VERSION ""

NS_ :

BS_:

BU_: VCU

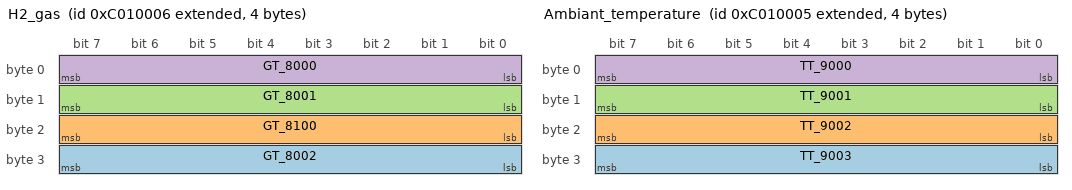
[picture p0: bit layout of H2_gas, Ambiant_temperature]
BO_ 2348875782 H2_gas: 4 Vector__XXX
 SG_ GT_8002 : 24|8@1+ (0.02,0) [0|5.1] "" Vector__XXX
 SG_ GT_8100 : 16|8@1+ (0.02,0) [0|5.1] "" Vector__XXX
 SG_ GT_8001 : 8|8@1+ (0.02,0) [0|5.1] "" Vector__XXX
 SG_ GT_8000 : 0|8@1+ (0.02,0) [0|5.1] "" Vector__XXX

BO_ 2348875781 Ambiant_temperature: 4 Vector__XXX
 SG_ TT_9003 : 24|8@1- (1,0) [-128|127] "" Vector__XXX
 SG_ TT_9002 : 16|8@1- (1,0) [-128|127] "" Vector__XXX
 SG_ TT_9001 : 8|8@1- (1,0) [-128|127] "" Vector__XXX
 SG_ TT_9000 : 0|8@1- (1,0) [-128|127] "" Vector__XXX

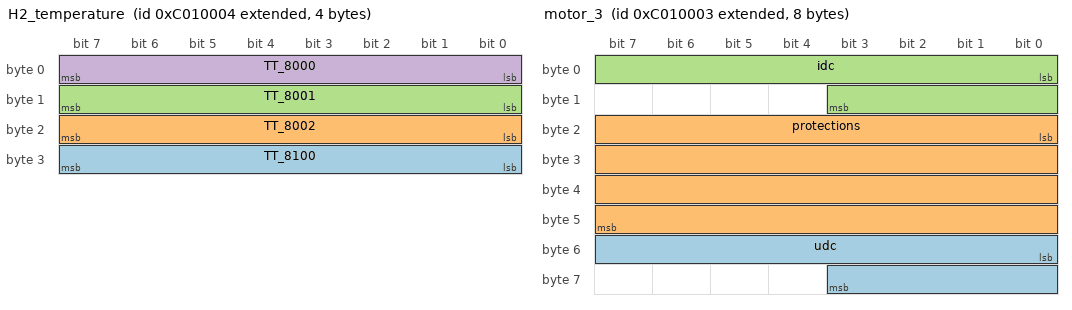
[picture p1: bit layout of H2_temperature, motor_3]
BO_ 2348875780 H2_temperature: 4 Vector__XXX
 SG_ TT_8100 : 24|8@1- (1,0) [-128|127] "" Vector__XXX
 SG_ TT_8002 : 16|8@1- (1,0) [-128|127] "" Vector__XXX
 SG_ TT_8001 : 8|8@1- (1,0) [-128|127] "" Vector__XXX
 SG_ TT_8000 : 0|8@1- (1,0) [-128|127] "" Vector__XXX

BO_ 2348875779 motor_3: 8 Vector__XXX
 SG_ udc : 48|12@1+ (0.2,0) [0|819] "" Vector__XXX
 SG_ protections : 16|32@1+ (1,0) [0|4294967295] "" Vector__XXX
 SG_ idc : 0|12@1+ (0.5,0) [0|2047.5] "" Vector__XXX

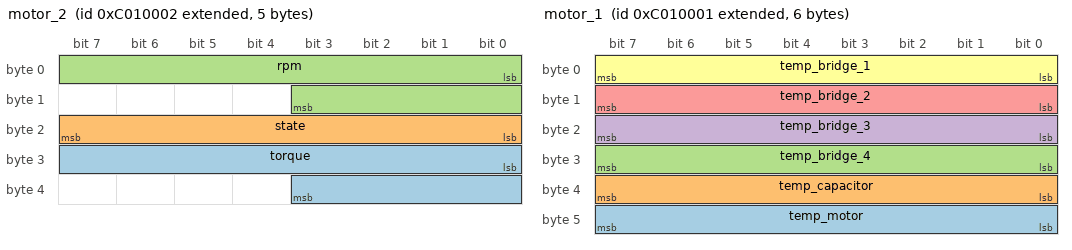
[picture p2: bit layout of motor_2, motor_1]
BO_ 2348875778 motor_2: 5 Vector__XXX
 SG_ torque : 24|12@1+ (1,0) [0|4095] "" Vector__XXX
 SG_ state : 16|8@1- (1,0) [-128|127] "" Vector__XXX
 SG_ rpm : 0|12@1+ (1,0) [0|4095] "" Vector__XXX

BO_ 2348875777 motor_1: 6 Vector__XXX
 SG_ temp_motor : 40|8@1- (1,0) [-128|127] "" Vector__XXX
 SG_ temp_capacitor : 32|8@1- (1,0) [-128|127] "" Vector__XXX
 SG_ temp_bridge_4 : 24|8@1- (1,0) [-128|127] "" Vector__XXX
 SG_ temp_bridge_3 : 16|8@1- (1,0) [-128|127] "" Vector__XXX
 SG_ temp_bridge_2 : 8|8@1- (1,0) [-128|127] "" Vector__XXX
 SG_ temp_bridge_1 : 0|8@1- (1,0) [-128|127] "" Vector__XXX

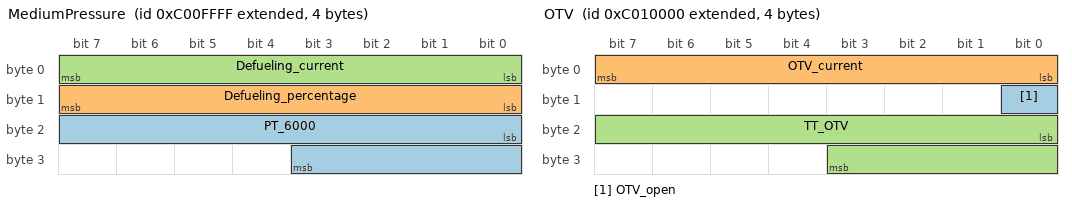
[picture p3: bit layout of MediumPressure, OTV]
BO_ 2348875775 MediumPressure: 4 Vector__XXX
 SG_ PT_6000 : 16|12@1+ (0.01,0) [0|40.95] "barg"  VCU
 SG_ Defueling_percentage : 8|8@1+ (0.5,0) [0|127.5] "%"  VCU
 SG_ Defueling_current : 0|8@1- (0.05,0) [-6.4|6.35] "A"  VCU

BO_ 2348875776 OTV: 4 Vector__XXX
 SG_ OTV_open : 8|1@1- (1,0) [-1|0] ""  VCU
 SG_ OTV_current : 0|8@1- (0.015,0) [-1.92|1.905] "A"  VCU
 SG_ TT_OTV : 16|12@1- (0.15,0) [-307.2|307.05] "C"  VCU

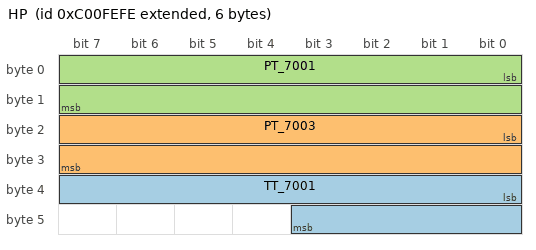
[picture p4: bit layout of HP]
BO_ 2348875518 HP: 6 Vector__XXX
 SG_ TT_7001 : 32|12@1- (0.15,0) [-307.2|307.05] "barg"  VCU
 SG_ PT_7003 : 16|16@1+ (0.02,0) [0|1310.7] "barg"  VCU
 SG_ PT_7001 : 0|16@1+ (0.02,0) [0|1310.7] "barg"  VCU

BA_DEF_ BO_  "J1939PgAppearanceOnBus" ENUM  "Default","CAN_Extended","CANFD_Extended";
BA_DEF_ BO_  "J1939CPgSendTimeout" INT -1 3600000;
BA_DEF_ BO_  "J1939CPgTOS" INT 0 7;
BA_DEF_ BU_  "J1939MultiPgSendTimeout" INT 0 3600000;
BA_DEF_ BU_  "J1939MultiPgSizeThreshold" INT 0 64;
BA_DEF_ BU_  "J1939MultiPgBroadcastType" ENUM  "FBFF","FEFF";
BA_DEF_ SG_  "SigType" ENUM  "Default","Range","RangeSigned","ASCII","Discrete","Control","ReferencePGN","DTC","StringDelimiter","StringLength","StringLengthControl","MessageCounter","MessageChecksum","LowerPartOfSPN";
BA_DEF_ SG_  "GenSigILSupport" ENUM  "No","Yes";
BA_DEF_ SG_  "GenSigSendType" ENUM  "Cyclic","OnWrite","OnWriteWithRepetition","OnChange","OnChangeWithRepetition","IfActive","IfActiveWithRepetition","NoSigSendType";
BA_DEF_ SG_  "GenSigStartValue" INT 0 2147483647;
BA_DEF_ BO_  "GenMsgILSupport" ENUM  "No","Yes";
BA_DEF_ BU_  "NmStationAddress" INT 0 255;
BA_DEF_ BO_  "GenMsgSendType" ENUM  "cyclic","NotUsed","NotUsed","NotUsed","NotUsed","NotUsed","NotUsed","IfActive","noMsgSendType";
BA_DEF_ BO_  "GenMsgRequestable" INT 0 1;
BA_DEF_  "DBName" STRING ;
BA_DEF_  "BusType" STRING ;
BA_DEF_  "ProtocolType" STRING ;
BA_DEF_ BO_  "VFrameFormat" ENUM  "StandardCAN","ExtendedCAN","reserved","J1939PG","reserved","reserved","reserved","reserved","reserved","reserved","reserved","reserved","reserved","reserved","StandardCAN_FD","ExtendedCAN_FD";
BA_DEF_DEF_  "J1939PgAppearanceOnBus" "Default";
BA_DEF_DEF_  "J1939CPgSendTimeout" -1;
BA_DEF_DEF_  "J1939CPgTOS" 2;
BA_DEF_DEF_  "J1939MultiPgSendTimeout" 2;
BA_DEF_DEF_  "J1939MultiPgSizeThreshold" 56;
BA_DEF_DEF_  "J1939MultiPgBroadcastType" "FBFF";
BA_DEF_DEF_  "SigType" "Default";
BA_DEF_DEF_  "GenSigILSupport" "Yes";
BA_DEF_DEF_  "GenSigSendType" "NoSigSendType";
BA_DEF_DEF_  "GenSigStartValue" 0;
BA_DEF_DEF_  "GenMsgILSupport" "Yes";
BA_DEF_DEF_  "NmStationAddress" 254;
BA_DEF_DEF_  "GenMsgSendType" "noMsgSendType";
BA_DEF_DEF_  "GenMsgRequestable" 1;
BA_DEF_DEF_  "DBName" "";
BA_DEF_DEF_  "BusType" "CAN";
BA_DEF_DEF_  "ProtocolType" "J1939";
BA_DEF_DEF_  "VFrameFormat" "J1939PG";
BA_ "DBName" "VCU";
BA_ "NmStationAddress" BU_ VCU 0;
BA_ "VFrameFormat" BO_ 2348875782 1;
BA_ "VFrameFormat" BO_ 2348875781 1;
BA_ "VFrameFormat" BO_ 2348875780 1;
BA_ "VFrameFormat" BO_ 2348875779 1;
BA_ "VFrameFormat" BO_ 2348875778 1;
BA_ "VFrameFormat" BO_ 2348875777 1;
BA_ "VFrameFormat" BO_ 2348875775 1;
BA_ "VFrameFormat" BO_ 2348875776 1;
BA_ "VFrameFormat" BO_ 2348875518 1;
